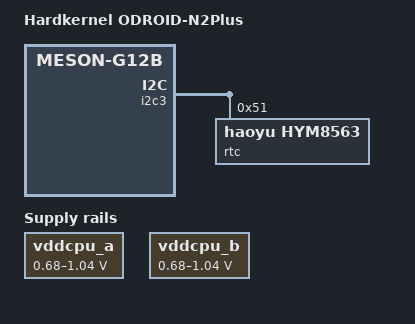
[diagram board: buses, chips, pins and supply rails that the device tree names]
// SPDX-License-Identifier: (GPL-2.0+ OR MIT)
/*
 * Copyright (c) 2019 BayLibre, SAS
 * Author: Neil Armstrong <narmstrong@baylibre.com>
 */

/dts-v1/;

/* The Amlogic S922X Rev. C supports the same OPPs as the A311D variant */
#include "meson-g12b-a311d.dtsi"
#include "meson-g12b-odroid-n2.dtsi"

/ {
	compatible = "hardkernel,odroid-n2-plus", "amlogic,s922x", "amlogic,g12b";
	model = "Hardkernel ODROID-N2Plus";

	aliases {
		rtc0 = &rtc;
		rtc1 = &vrtc;
	};
};

&i2c3 {
	status = "okay";
	pinctrl-0 = <&i2c3_sda_a_pins>, <&i2c3_sck_a_pins>;
	pinctrl-names = "default";

	rtc: rtc@51 {
		compatible = "haoyu,hym8563";
		reg = <0x51>;
		wakeup-source;
	};
};

&vddcpu_a {
	regulator-min-microvolt = <680000>;
	regulator-max-microvolt = <1040000>;

	pwms = <&pwm_ab 0 1500 0>;
};

&vddcpu_b {
	regulator-min-microvolt = <680000>;
	regulator-max-microvolt = <1040000>;

	pwms = <&pwm_AO_cd 1 1500 0>;
};

